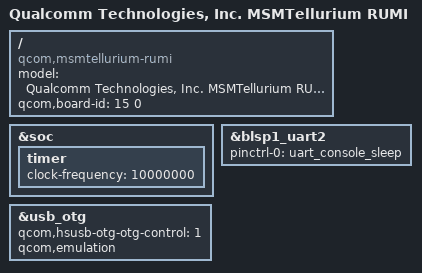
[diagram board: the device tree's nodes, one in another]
/*
 * Copyright (c) 2014-2015, The Linux Foundation. All rights reserved.
 *
 * This program is free software; you can redistribute it and/or modify
 * it under the terms of the GNU General Public License version 2 and
 * only version 2 as published by the Free Software Foundation.
 *
 * This program is distributed in the hope that it will be useful,
 * but WITHOUT ANY WARRANTY; without even the implied warranty of
 * MERCHANTABILITY or FITNESS FOR A PARTICULAR PURPOSE.  See the
 * GNU General Public License for more details.
 */

/dts-v1/;

#include "msmtellurium.dtsi"

/ {
	model = "Qualcomm Technologies, Inc. MSMTellurium RUMI";
	compatible = "qcom,msmtellurium-rumi", "qcom,msmtellurium", "qcom,rumi";
	qcom,board-id= <15 0>;
};

&soc {
	timer {
		clock-frequency = <10000000>;
	};
};

&blsp1_uart2 {
	status = "ok";
	pinctrl-names = "default";
	pinctrl-0 = <&uart_console_sleep>;
};

&usb_otg {
	qcom,hsusb-otg-otg-control = <1>;
	qcom,emulation;
};
